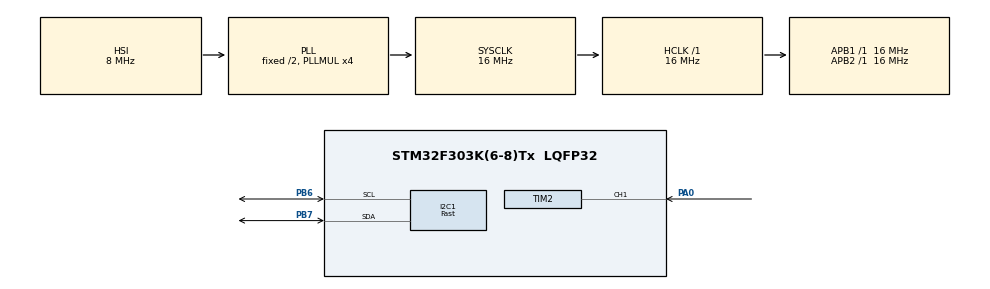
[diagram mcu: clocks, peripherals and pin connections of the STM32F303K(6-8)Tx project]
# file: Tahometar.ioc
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I2C1.I2C_Speed_Mode=I2C_Fast
I2C1.Timing=0x0000020B
Mcu.Family=STM32F3
Mcu.Name=STM32F303K(6-8)Tx
Mcu.Package=LQFP32
NVIC.PriorityGroup=NVIC_PRIORITYGROUP_4
NVIC.TIM2_IRQn=true\:0\:0\:false\:false\:true\:true\:true\:true
PA0.Signal=S_TIM2_CH1_ETR
PA13.Mode=Serial_Wire
PA13.Signal=SYS_JTMS-SWDIO
PA14.Mode=Serial_Wire
PA14.Signal=SYS_JTCK-SWCLK
PB6.Mode=I2C
PB6.Signal=I2C1_SCL
PB7.Mode=I2C
PB7.Signal=I2C1_SDA
ProjectManager.HeapSize=0x200
ProjectManager.StackSize=0x400
ProjectManager.TargetToolchain=STM32CubeIDE
RCC.AHBFreq_Value=16000000
RCC.APB1Freq_Value=16000000
RCC.APB1TimFreq_Value=16000000
RCC.APB2Freq_Value=16000000
RCC.APB2TimFreq_Value=16000000
RCC.CortexFreq_Value=16000000
RCC.HCLKFreq_Value=16000000
RCC.HSE_VALUE=8000000
RCC.HSI_VALUE=8000000
RCC.PLLMUL=RCC_PLL_MUL4
RCC.SYSCLKFreq_VALUE=16000000
RCC.SYSCLKSourceVirtual=RCC_SYSCLKSOURCE_PLLCLK
SH.S_TIM2_CH1_ETR.0=TIM2_CH1,Input_Capture1_from_TI1
TIM2.Channel-Input_Capture1_from_TI1=TIM_CHANNEL_1
TIM2.Period=65535
TIM2.Prescaler=15999
board=custom

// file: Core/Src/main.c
/* USER CODE BEGIN Header */
/**
  ******************************************************************************
  * @file           : main.c
  * @brief          : Main program body
  ******************************************************************************
  * @attention
  *
  * Copyright (c) 2023 STMicroelectronics.
  * All rights reserved.
  *
  * This software is licensed under terms that can be found in the LICENSE file
  * in the root directory of this software component.
  * If no LICENSE file comes with this software, it is provided AS-IS.
  *
  ******************************************************************************
  */
/* USER CODE END Header */
#include "main.h"
#include "i2c.h"
#include "tim.h"
#include "gpio.h"

/* USER CODE BEGIN Includes */
#include "ssd1306.h"
#include "ssd1306_tests.h"

#include <stdio.h>
#include <stdlib.h>
#include <string.h>
/* USER CODE END Includes */

void SystemClock_Config(void);

/* USER CODE BEGIN 0 */
uint16_t T1=0, T2=0, zastavica=1, counter;
float W, T;
char tekst[16];
/* USER CODE END 0 */

int main(void)
{

  /* MCU Configuration--------------------------------------------------------*/

  /* Reset of all peripherals, Initializes the Flash interface and the Systick. */
  HAL_Init();

  /* Configure the system clock */
  SystemClock_Config();

  /* Initialize all configured peripherals */
  MX_GPIO_Init();
  MX_I2C1_Init();
  MX_TIM2_Init();
  /* USER CODE BEGIN 2 */
  HAL_TIM_IC_Start_IT(&htim2, TIM_CHANNEL_1);
  ssd1306_Init();
  /* USER CODE END 2 */

  /* Infinite loop */
  while (1)
  {
	  ssd1306_Fill(Black); //ispuna ekrane crnom bojom

	  ssd1306_SetCursor(25, 19); //postavljanje pokazivača
	  ssd1306_WriteString(tekst, Font_16x26, White); //ispisivanje teksta

	  ssd1306_UpdateScreen(); //osvježavanje ekrana
	  HAL_Delay(200); //odgoda
  }
}

void HAL_TIM_IC_CaptureCallback(TIM_HandleTypeDef* htim){

	if(zastavica==1){
		T1=TIM2->CCR1; //zapisivanje vrijednosti timera kod prvog prolaza
		zastavica=2;
	}

	else if(zastavica==2){

		T2=TIM2->CCR1; //zapisivanje vrijednosti timera kod drugog prolaza
		T=(T2-T1)/2.0; //računanje razlike
		W=60000.0/T; //računanje kružne frekvencije
	  	itoa(W,tekst,10); //pretvaranje float varijable u string
	  	zastavica=1;
	  	T1=0; //resetiranje varijabli
	  	T2=0;
	}

}

void SystemClock_Config(void)
{
  RCC_OscInitTypeDef RCC_OscInitStruct = {0};
  RCC_ClkInitTypeDef RCC_ClkInitStruct = {0};
  RCC_PeriphCLKInitTypeDef PeriphClkInit = {0};

  /** Initializes the RCC Oscillators according to the specified parameters
  * in the RCC_OscInitTypeDef structure.
  */
  RCC_OscInitStruct.OscillatorType = RCC_OSCILLATORTYPE_HSI;
  RCC_OscInitStruct.HSIState = RCC_HSI_ON;
  RCC_OscInitStruct.HSICalibrationValue = RCC_HSICALIBRATION_DEFAULT;
  RCC_OscInitStruct.PLL.PLLState = RCC_PLL_ON;
  RCC_OscInitStruct.PLL.PLLSource = RCC_PLLSOURCE_HSI;
  RCC_OscInitStruct.PLL.PLLMUL = RCC_PLL_MUL4;
  if (HAL_RCC_OscConfig(&RCC_OscInitStruct) != HAL_OK)
  {
    Error_Handler();
  }

  /** Initializes the CPU, AHB and APB buses clocks
  */
  RCC_ClkInitStruct.ClockType = RCC_CLOCKTYPE_HCLK|RCC_CLOCKTYPE_SYSCLK
                              |RCC_CLOCKTYPE_PCLK1|RCC_CLOCKTYPE_PCLK2;
  RCC_ClkInitStruct.SYSCLKSource = RCC_SYSCLKSOURCE_PLLCLK;
  RCC_ClkInitStruct.AHBCLKDivider = RCC_SYSCLK_DIV1;
  RCC_ClkInitStruct.APB1CLKDivider = RCC_HCLK_DIV1;
  RCC_ClkInitStruct.APB2CLKDivider = RCC_HCLK_DIV1;

  if (HAL_RCC_ClockConfig(&RCC_ClkInitStruct, FLASH_LATENCY_0) != HAL_OK)
  {
    Error_Handler();
  }
  PeriphClkInit.PeriphClockSelection = RCC_PERIPHCLK_I2C1;
  PeriphClkInit.I2c1ClockSelection = RCC_I2C1CLKSOURCE_HSI;
  if (HAL_RCCEx_PeriphCLKConfig(&PeriphClkInit) != HAL_OK)
  {
    Error_Handler();
  }
}

void Error_Handler(void)
{
  __disable_irq();
  while (1)
  {
  }
}
